# MK70F12 register map
Vendor: Freescale Semiconductor, Inc.; Series: Kinetis_K; File version: 1.6
CPU: CM4 r0p1, little endian, no MPU, FPU, VTOR, 4 interrupt priority bits
Registers are 32-bit, read-write, reset 0x0 unless marked. A register's access mark holds for its fields unless they carry their own. Offsets are from the block's base; [hi:lo] are bit positions; {n}, {i} and the like mark numbered series.

## USBHS — USB HS/FS/LS OTG Controller
Base 0x40034000; register names take the prefix USBHS_
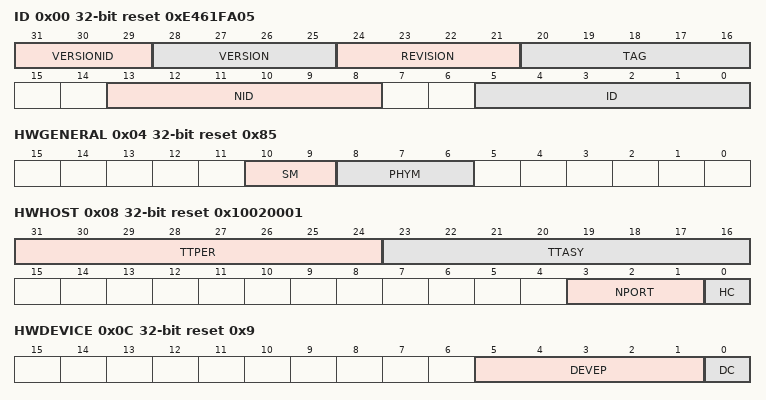
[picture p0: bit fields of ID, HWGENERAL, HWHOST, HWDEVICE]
0x00 ID ro reset 0xE461FA05 — Identification Register
  [31:29] VERSIONID
  [28:25] VERSION
  [24:21] REVISION
  [20:16] TAG
  [13:8] NID — Ones complement version of ID.
  [5:0] ID — Configuration number
0x04 HWGENERAL ro reset 0x85 — General Hardware Parameters Register
  [10:9] SM — Serial mode
  [8:6] PHYM — PHY Mode
0x08 HWHOST ro reset 0x10020001 — Host Hardware Parameters Register
  [31:24] TTPER — Transaction translator periodic contexts.
  [23:16] TTASY — Transaction translator contexts.
  [3:1] NPORT — Number of Ports
  [0] HC — Host Capable
0x0C HWDEVICE ro reset 0x9 — Device Hardware Parameters Register
  [5:1] DEVEP — Device endpoints.
  [0] DC — Device Capable
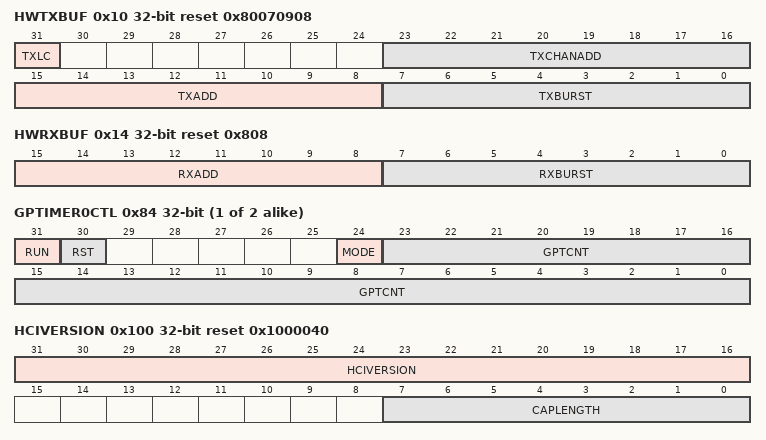
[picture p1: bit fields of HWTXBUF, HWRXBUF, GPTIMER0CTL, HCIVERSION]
0x10 HWTXBUF ro reset 0x80070908 — Transmit Buffer Hardware Parameters Register
  [31] TXLC — Transmit local Context Registers
    0=Store device transmit contexts in the TX FIFO; 1=Store device transmit contexts in a register file
  [23:16] TXCHANADD — Transmit Channel Address
  [15:8] TXADD — Transmit Address.
  [7:0] TXBURST — Transmit Burst.
0x14 HWRXBUF ro reset 0x808 — Receive Buffer Hardware Parameters Register
  [15:8] RXADD — Receive Address.
  [7:0] RXBURST — Receive Burst.
{0x80+8i} GPTIMER{i}LD (i=0..1) — General Purpose Timer n Load Register
  [23:0] GPTLD
{0x84+8i} GPTIMER{i}CTL (i=0..1) — General Purpose Timer n Control Register
  [31] RUN — Timer Run
    0=Timer stop; 1=Timer run
  [30] RST wo — Timer Reset
    0=No action; 1=Load counter value
  [24] MODE — Timer Mode
    0=One shot; 1=Repeat
  [23:0] GPTCNT ro — Timer Count
0x90 USB_SBUSCFG — System Bus Interface Configuration Register
  [2:0] BURSTMODE
    0=INCR burst of unspecified length; 1=INCR4, non-multiple transfers of INCR4 is decomposed into singles; 2=INCR8, non-multiple transfers of INCR8, is decomposed into INCR4 or singles; 3=INCR16, non-multiple transfers of INCR16, is decomposed into INCR8, INCR4 or singles; 4=Reserved, do not use; 5=INCR4, non-multiple transfers of INCR4 is decomposed into smaller unspecified length bursts; 6=INCR8, non-multiple transfers of INCR8 is decomposed into smaller unspecified length bursts; 7=INCR16, non-multiple transfers of INCR16 is decomposed into smaller unspecified length bursts
0x100 HCIVERSION ro reset 0x1000040 — Host Controller Interface Version and Capability Registers Length Register
  [31:16] HCIVERSION — EHCI revision number
  [7:0] CAPLENGTH — Capability registers length
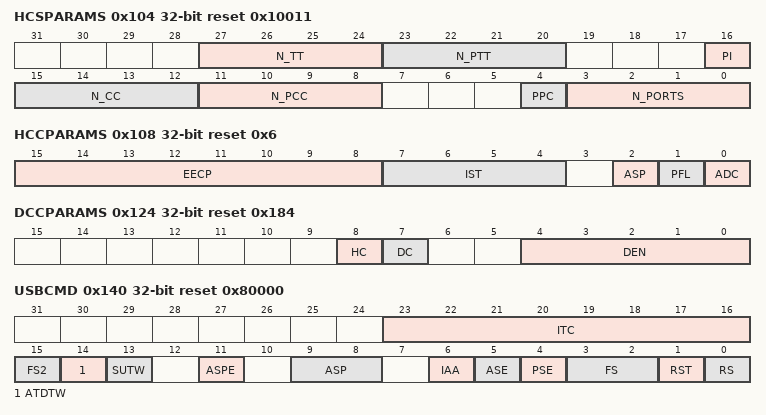
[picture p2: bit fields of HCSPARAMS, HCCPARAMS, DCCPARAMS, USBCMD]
0x104 HCSPARAMS ro reset 0x10011 — Host Controller Structural Parameters Register
  [27:24] N_TT — Number of Transaction Translators.
  [23:20] N_PTT — Ports per Transaction Translator
  [16] PI — Port Indicators
    0=No port indicator fields; 1=The port status and control registers include a R/W field for controlling the state of the port indicator
  [15:12] N_CC — Number of Companion Controllers
  [11:8] N_PCC — Number Ports per CC
  [4] PPC — Power Port Control
    1=Ports have power port switches
  [3:0] N_PORTS — Number of Ports
0x108 HCCPARAMS ro reset 0x6 — Host Controller Capability Parameters Register
  [15:8] EECP — EHCI Extended Capabilities Pointer
    0=No extended capabilities are implemented
  [7:4] IST — Isochronous Scheduling Threshold
    0=The value of the least significant 3 bits indicates the number of microframes a host controller can hold a set of isochronous data structures (one or more) before flushing the state
  [2] ASP — Asynchronous Schedule Park capability
    0=Park not supported; 1=Park supported
  [1] PFL — Programmable Frame List flag
  [0] ADC — 64-bit addressing capability.
0x122 DCIVERSION 16-bit ro reset 0x1 — Device Controller Interface Version
  [15:0] DCIVERSION — Device interface revision number.
0x124 DCCPARAMS ro reset 0x184 — Device Controller Capability Parameters
  [8] HC — Host Capable
  [7] DC — Device Capable
  [4:0] DEN — Device Endpoint Number
0x140 USBCMD reset 0x80000 — USB Command Register
  [23:16] ITC — Interrupt Threshold Control
    0=Immediate (no threshold); 1=1 microframe; 2=2 microframes; 4=4 microframes; 8=8 microframes; 16=16 microframes; 32=32 microframes; 64=64 microframes
  [15] FS2 — Frame list Size 2
  [14] ATDTW — Add dTD TripWire
  [13] SUTW — Setup TripWire
  [11] ASPE — Asynchronous Schedule Park mode Enable
    0=Park mode disabled; 1=Park mode enabled
  [9:8] ASP — Asynchronous Schedule Park mode count
  [6] IAA — Interrupt on Async Advance doorbell
  [5] ASE — Asynchronous Schedule Enable
    0=Do not process asynchronous schedule; 1=Use the ASYNCLISTADDR register to access asynchronous schedule
  [4] PSE — Periodic Schedule Enable
    0=Do not process periodic schedule; 1=Use the PERIODICLISTBASE register to access the periodic schedule
  [3:2] FS — Frame list Size
    0=When FS2 = 0, the size is 1024 elements (4096 bytes). When FS2 = 1, the size is 64 elements (256 bytes).; 1=When FS2 = 0, the size is 512 elements (2048 bytes). When FS2 = 1, the size is 32 elements (128 bytes).; 2=When FS2 = 0, the size is 256 elements (1024 bytes). When FS2 = 1, the size is 16 elements (64 bytes).; 3=When FS2 = 0, the size is 128 elements (512 bytes). When FS2 = 1, the size is 8 elements (32 bytes).
  [1] RST — Controller Reset
  [0] RS — Run/Stop
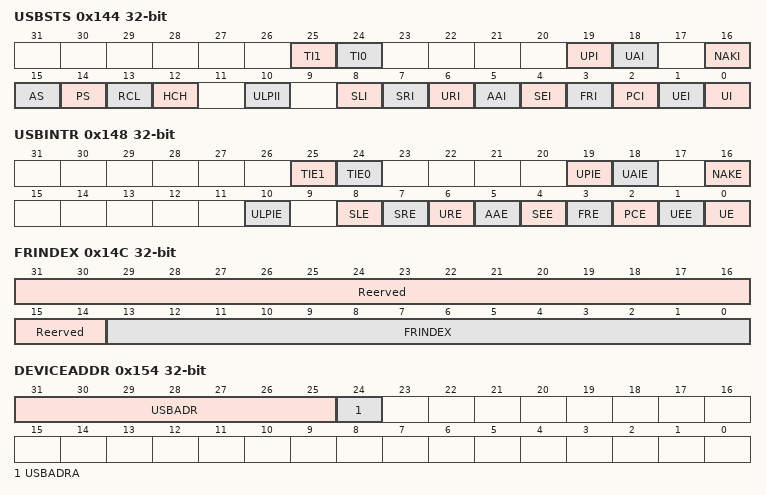
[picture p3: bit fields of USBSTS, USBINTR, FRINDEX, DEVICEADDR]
0x144 USBSTS — USB Status Register
  [25] TI1 — General purpose Timer 1 Interrupt
    0=No interrupt; 1=Interrupt occurred
  [24] TI0 — General purpose Timer 0 Interrupt
    0=No interrupt; 1=Interrupt occurred
  [19] UPI — USB host Periodic Interrupt
  [18] UAI — USB host Asynchronous Interrupt
  [16] NAKI ro — NAK Interrupt
  [15] AS ro — Asynchronous schedule Status
    0=Disabled; 1=Enabled
  [14] PS ro — Periodic schedule Status
    0=Disabled; 1=Enabled
  [13] RCL ro — Reclamation
    0=Non-empty asynchronous schedule; 1=Empty asynchronous schedule
  [12] HCH ro — Host Controller Halted
    0=Running; 1=Halted
  [10] ULPII ro — ULPI Interrupt
  [8] SLI — Device-controller suspend
    0=Active; 1=Suspended
  [7] SRI — SOF Received
  [6] URI — USB Reset received
    0=No reset received; 1=Reset received
  [5] AAI — Interrupt on Async Advance
    0=No async advance interrupt; 1=Async advance interrupt
  [4] SEI — System Error
    0=Normal operation; 1=Error
  [3] FRI — Frame-list Rollover
  [2] PCI — Port Change detect
  [1] UEI — USB Error Interrupt
    0=No error; 1=Error detected
  [0] UI — USB Interrupt (USBINT)
0x148 USBINTR — USB Interrupt Enable Register
  [25] TIE1 — General purpose Timer 1 Interrupt Enable
    0=Disabled; 1=Enabled
  [24] TIE0 — General purpose Timer 0 Interrupt Enable
    0=Disabled; 1=Enabled
  [19] UPIE — USB host Periodic Interrupt Enable
  [18] UAIE — USB host Asynchronous Interrupt Enable
  [16] NAKE — NAK Interrupt Enable
    0=Disabled; 1=Enabled
  [10] ULPIE — ULPI Enable
  [8] SLE — Sleep (DC suspend) Enable
    0=Disabled; 1=Enabled
  [7] SRE — SOF-Received Enable
    0=Disabled; 1=Enabled
  [6] URE — USB-Reset Enable
    0=Disabled; 1=Enabled
  [5] AAE — Interrupt on Async advance Enable
    0=Disabled; 1=Enabled
  [4] SEE — System Error Enable
    0=Disabled; 1=Enabled
  [3] FRE — Frame list Rollover Enable
    0=Disabled; 1=Enabled
  [2] PCE — Port Change detect Enable
    0=Disabled; 1=Enabled
  [1] UEE — USB Error interrupt Enable
    0=Disabled; 1=Enabled
  [0] UE — USB interrupt Enable
    0=Disabled; 1=Enabled
0x14C FRINDEX — Frame Index Register
  [31:14] Reerved ro — Reserved
  [13:0] FRINDEX — Frame Index
0x154 DEVICEADDR (USBHS view) — Device Address Register
  [31:25] USBADR — Device Address
  [24] USBADRA — Device Address Advance
    0=Writes to USBADR are instantaneous; 1=When this bit is written to a 1 at the same time or before USBADR is written, the write to the USBADR field is staged and held in a hidden register. After an IN occurs on endpoint 0 and is ACKed, USBADR is loaded from the holding register.
0x154 PERIODICLISTBASE (USBHS view) — Periodic Frame List Base Address Register
  [31:12] PERBASE — Base address
0x158 ASYNCLISTADDR (USBHS view) — Current Asynchronous List Address Register
  [31:5] ASYBASE — Link pointer low (LPL)
0x158 EPLISTADDR (USBHS view) — Endpoint List Address Register
  [31:11] EPBASE — Endpoint list address
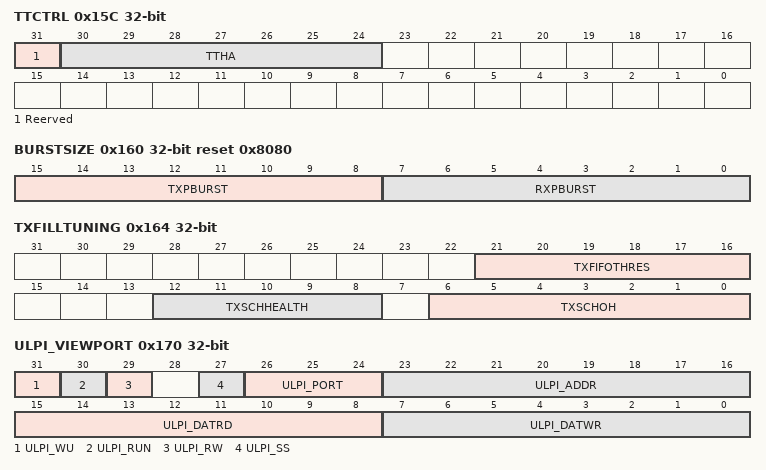
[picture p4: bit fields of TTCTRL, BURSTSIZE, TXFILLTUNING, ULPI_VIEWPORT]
0x15C TTCTRL ro — Host TT Asynchronous Buffer Control
  [31] Reerved — Reserved
  [30:24] TTHA — TT Hub Address
0x160 BURSTSIZE reset 0x8080 — Master Interface Data Burst Size Register
  [15:8] TXPBURST — Programable TX Burst length
  [7:0] RXPBURST — Programable RX Burst length
0x164 TXFILLTUNING — Transmit FIFO Tuning Control Register
  [21:16] TXFIFOTHRES — FIFO burst Threshold
  [12:8] TXSCHHEALTH — Scheduler Health counter
  [6:0] TXSCHOH — Scheduler Overhead
0x170 ULPI_VIEWPORT — ULPI Register Access
  [31] ULPI_WU — ULPI Wake-Up
  [30] ULPI_RUN
  [29] ULPI_RW — ULPI Read/Write
    0=Read; 1=Write
  [27] ULPI_SS — ULPI Sync State
    0=Any other state (that is, carkit, serial, low power); 1=Normal sync state
  [26:24] ULPI_PORT — ULPI Port number
  [23:16] ULPI_ADDR — ULPI data Address
  [15:8] ULPI_DATRD ro — ULPI Data Read
  [7:0] ULPI_DATWR — ULPI Data Write
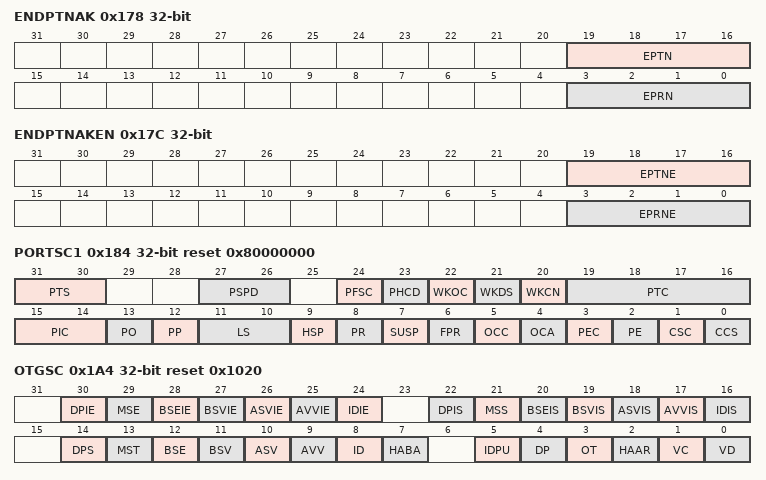
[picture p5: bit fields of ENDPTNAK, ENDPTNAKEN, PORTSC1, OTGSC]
0x178 ENDPTNAK — Endpoint NAK Register
  [19:16] EPTN — TX Endpoint NAK
  [3:0] EPRN — RX Endpoint NAK
0x17C ENDPTNAKEN — Endpoint NAK Enable Register
  [19:16] EPTNE — TX Endpoint NAK
  [3:0] EPRNE — RX Endpoint NAK
0x180 CONFIGFLAG ro reset 0x1 — Configure Flag Register
0x184 PORTSC1 reset 0x80000000 — Port Status and Control Registers
  [31:30] PTS — Port Transceiver Select
  [27:26] PSPD ro — Port Speed
    0=Full speed; 1=Low speed; 2=High speed; 3=Undefined
  [24] PFSC — Port force Full-Speed Connect
    0=Allow the port to identify itself as high speed; 1=Force the port to only connect at full speed
  [23] PHCD — PHY low power suspend
  [22] WKOC — Wake on Over-Current enable
  [21] WKDS — Wake on Disconnect enable
  [20] WKCN — Wake on Connect enable
  [19:16] PTC — Port Test Control
    0=Not enabled; 1=J_STATE; 2=K_STATE; 3=SEQ_NAK; 4=Packet; 5=FORCE_ENABLE_HS; 6=FORCE_ENABLE_FS; 7=FORCE_ENABLE_LS
  [15:14] PIC — Port Indicator Control
  [13] PO — Port Owner
  [12] PP — Port Power
  [11:10] LS ro — Line Status
    0=SE0; 1=J-state; 2=K-state; 3=Undefined
  [9] HSP ro — High Speed Port.
    0=FS or LS; 1=HS
  [8] PR — Port Reset
    0=Port is not in reset; 1=Port is in reset
  [7] SUSP — Suspend
    0=Port not in suspend state; 1=Port in suspend state
  [6] FPR — Force Port Resume
    0=No resume (K-state) detected/driven on port; 1=Resume detected/driven on port
  [5] OCC — Over-Current Change
    0=No over-current; 1=Over-current detect
  [4] OCA ro — Over-current active
    0=Port not in over-current condition; 1=Port currently in over-current condition
  [3] PEC — Port Enable/disable Change
    0=No change; 1=Port disabled
  [2] PE — Port Enabled/disabled
  [1] CSC — Connect Change Status
    0=No change; 1=Connect status has changed
  [0] CCS ro — Current Connect Status
    0=No device present (host mode) or attached (device mode); 1=Device is present (host mode) or attached (device mode)
0x1A4 OTGSC reset 0x1020 — On-the-Go Status and Control Register
  [30] DPIE — Data Pulse Interrupt Enable
    0=Disable; 1=Enable
  [29] MSE — 1 Milli-Second timer interrupt Enable
    0=Disable; 1=Enable
  [28] BSEIE — B Session End Interrupt Enable
    0=Disable; 1=Enable
  [27] BSVIE — B Session Valid Interrupt Enable
    0=Disable; 1=Enable
  [26] ASVIE — A Session Valid Interrupt Enable
    0=Disable; 1=Enable
  [25] AVVIE — A VBUS Valid Interrupt Enable
    0=Disable; 1=Enable
  [24] IDIE — USB ID Interrupt Enable
    0=Disable; 1=Enable
  [22] DPIS — Data Pulse interrupt Status
  [21] MSS — 1 Milli-Second timer interrupt Status
  [20] BSEIS — B Session End Interrupt Status
  [19] BSVIS — B Session Valid Interrupt Status
  [18] ASVIS — A Session Valid Interrupt Status
  [17] AVVIS — A VBUS Valid Interrupt Status
  [16] IDIS — USB ID Interrupt Status
  [14] DPS ro — Data bus Pulsing Status
    0=No pulsing on port; 1=Pulsing detected on port
  [13] MST ro — 1 Milli-Second timer Toggle
  [12] BSE ro — B Session End
    0=VBus is above B session end threshold; 1=VBus is below B session end threshold
  [11] BSV ro — B Session Valid
    0=VBus is below B session valid threshold; 1=VBus is above B session valid threshold
  [10] ASV ro — A Session Valid
    0=VBus is below A session valid threshold; 1=VBus is above A session valid threshold
  [9] AVV ro — A VBus Valid
    0=VBus is below A VBus valid threshold; 1=VBus is above A VBus valid threshold
  [8] ID ro — USB ID
    0=A device; 1=B device
  [7] HABA — Hardware Assist B-Disconnect to A-connect
    0=Disabled; 1=Enable automatic B-disconnect to A-connect sequence
  [5] IDPU — ID Pull-Up
    0=Disable pull-up. ID input not sampled.; 1=Enable pull-up
  [4] DP — Data Pulsing
    0=The pull-up on DP is not asserted; 1=The pull-up on DP is asserted for data pulsing during SRP
  [3] OT — OTG Termination
    0=Disable pull-down on DM; 1=Enable pull-down on DM
  [2] HAAR — Hardware Assist Auto-Reset
    0=Disabled; 1=Enable automatic reset after connect on host port
  [1] VC — VBUS Charge
  [0] VD — VBUS Discharge
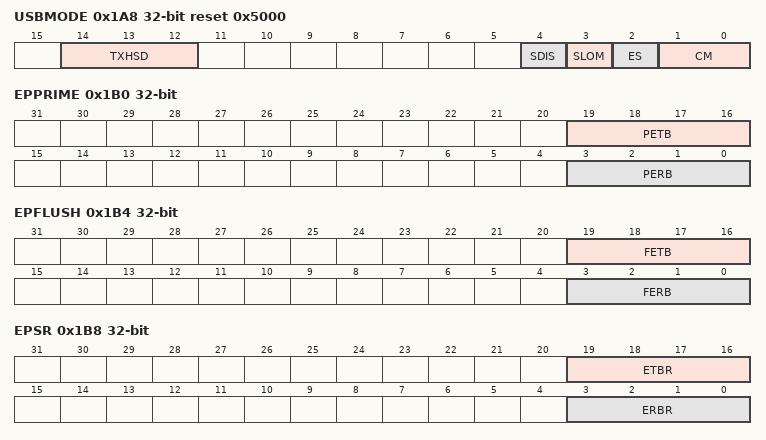
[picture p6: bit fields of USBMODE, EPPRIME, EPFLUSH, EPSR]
0x1A8 USBMODE reset 0x5000
  [14:12] TXHSD — Tx to Tx HS Delay
    {v}={v+10} (v=0..7)
  [4] SDIS — Stream DISable
    0=Inactive; 1=Active
  [3] SLOM — Setup Lock-Out Mode
  [2] ES — Endian Select
    0=Little endian. First byte referenced in least significant byte of 32-bit word.; 1=Big endian. First byte referenced in most significant byte of 32-bit word.
  [1:0] CM — Controller Mode
    0=Idle (default for the USBHS module); 2=Device controller; 3=Host controller
0x1AC EPSETUPSR — Endpoint Setup Status Register
  [3:0] EPSETUPSTAT — Setup Endpoint Status
0x1B0 EPPRIME — Endpoint Initialization Register
  [19:16] PETB — Prime Endpoint tTansmit Buffer
  [3:0] PERB — Prime Endpoint Receive Buffer
0x1B4 EPFLUSH — Endpoint Flush Register
  [19:16] FETB — Flush Endpoint Transmit Buffer
  [3:0] FERB — Flush Endpoint Receive Buffer
0x1B8 EPSR ro — Endpoint Status Register
  [19:16] ETBR — Endpoint Transmit Buffer Ready
  [3:0] ERBR — Endpoint Receive Buffer Ready
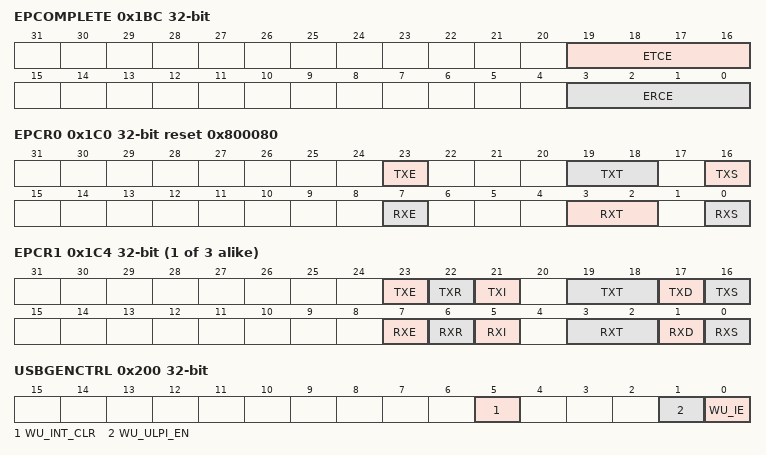
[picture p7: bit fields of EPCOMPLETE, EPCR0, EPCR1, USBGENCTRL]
0x1BC EPCOMPLETE — Endpoint Complete Register
  [19:16] ETCE — Endpoint Transmit Complete Event
  [3:0] ERCE — Endpoint Receive Complete Event
0x1C0 EPCR0 reset 0x800080 — Endpoint Control Register 0
  [23] TXE ro — TX Endpoint Enable
    1=Enable
  [19:18] TXT ro — TX Endpoint Type
    0=Control
  [16] TXS — TX Endpoint Stall
    0=Endpoint OK; 1=Endpoint stalled
  [7] RXE ro — RX endpoint Enable
    1=Enabled
  [3:2] RXT ro — RX endpoint Type
    0=Control
  [0] RXS — RX endpoint Stall
    0=Endpoint OK; 1=Endpoint stalled
{0x1C0+4i} EPCR{i} (i=1..3) — Endpoint Control Register n
  [23] TXE — TX endpoint Enable
    0=Disabled; 1=Enabled
  [22] TXR wo — TX data toggle Reset
  [21] TXI — TX data toggle Inhibit
    0=PID sequencing enabled; 1=PID sequencing disabled
  [19:18] TXT — TX endpoint Type
    0=Control; 1=Isochronous; 2=Bulk; 3=Interrupt
  [17] TXD — TX endpoint Data source
  [16] TXS — TX endpoint Stall
    0=Endpoint OK; 1=Endpoint stalled
  [7] RXE — RX endpoint Enable
    0=Disabled; 1=Enabled
  [6] RXR wo — RX data toggle Reset
  [5] RXI — RX data toggle Inhibit
    0=PID sequencing enabled; 1=PID sequencing disabled
  [3:2] RXT — RX endpoint Type
    0=Control; 1=Isochronous; 2=Bulk; 3=Interrupt
  [1] RXD — RX endpoint Data sink
  [0] RXS — RX endpoint Stall
    0=Endpoint OK; 1=Endpoint stalled
0x200 USBGENCTRL — USB General Control Register
  [5] WU_INT_CLR — Wakeup Interrupt Clear
    0=Default, no action; 1=Clear the wake-up interrupt
  [1] WU_ULPI_EN — Wakeup on ULPI Interrupt Event
    0=Disabled; 1=Enabled
  [0] WU_IE — Wakeup Interrupt Enable
    0=Disabled; 1=Enabled
